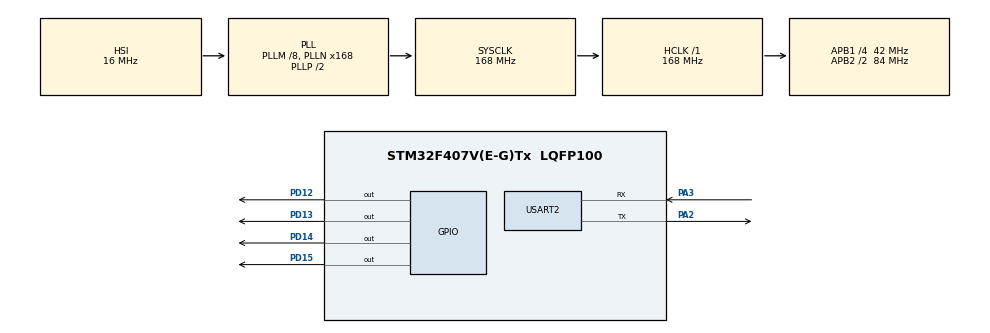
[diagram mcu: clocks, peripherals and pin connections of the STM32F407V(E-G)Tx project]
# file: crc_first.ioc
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Mcu.Family=STM32F4
Mcu.Name=STM32F407V(E-G)Tx
Mcu.Package=LQFP100
NVIC.PriorityGroup=NVIC_PRIORITYGROUP_4
NVIC.TIM1_UP_TIM10_IRQn=true\:0\:0\:false\:false\:true
NVIC.TimeBase=TIM1_UP_TIM10_IRQn
NVIC.TimeBaseIP=TIM1
PA13.Mode=Serial_Wire
PA13.Signal=SYS_JTMS-SWDIO
PA14.Mode=Serial_Wire
PA14.Signal=SYS_JTCK-SWCLK
PA2.Mode=Asynchronous
PA2.Signal=USART2_TX
PA3.Mode=Asynchronous
PA3.Signal=USART2_RX
PC14-OSC32_IN.Mode=LSE-External-Oscillator
PC14-OSC32_IN.Signal=RCC_OSC32_IN
PC15-OSC32_OUT.Mode=LSE-External-Oscillator
PC15-OSC32_OUT.Signal=RCC_OSC32_OUT
PD12.Signal=GPIO_Output
PD13.Signal=GPIO_Output
PD14.Signal=GPIO_Output
PD15.Signal=GPIO_Output
PH0-OSC_IN.Mode=HSE-External-Oscillator
PH0-OSC_IN.Signal=RCC_OSC_IN
PH1-OSC_OUT.Mode=HSE-External-Oscillator
PH1-OSC_OUT.Signal=RCC_OSC_OUT
ProjectManager.HeapSize=0x200
ProjectManager.StackSize=0x400
ProjectManager.TargetToolchain=MDK-ARM V5
RCC.48MHZClocksFreq_Value=84000000
RCC.AHBFreq_Value=168000000
RCC.APB1CLKDivider=RCC_HCLK_DIV4
RCC.APB1Freq_Value=42000000
RCC.APB1TimFreq_Value=84000000
RCC.APB2CLKDivider=RCC_HCLK_DIV2
RCC.APB2Freq_Value=84000000
RCC.APB2TimFreq_Value=168000000
RCC.CortexFreq_Value=168000000
RCC.HCLKFreq_Value=168000000
RCC.HSE_VALUE=8000000
RCC.HSI_VALUE=16000000
RCC.PLLM=8
RCC.PLLN=168
RCC.SYSCLKFreq_VALUE=168000000
RCC.SYSCLKSource=RCC_SYSCLKSOURCE_PLLCLK
RCC.VCOOutputFreq_Value=336000000
VP_CRC_VS_CRC.Mode=CRC_Activate
VP_SYS_VS_tim1.Mode=TIM1
board=crc_first

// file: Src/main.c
/**
  ******************************************************************************
  * File Name          : main.c
  * Description        : Main program body
  ******************************************************************************
  *
  * COPYRIGHT(c) 2017 STMicroelectronics
  *
  * Redistribution and use in source and binary forms, with or without modification,
  * are permitted provided that the following conditions are met:
  *   1. Redistributions of source code must retain the above copyright notice,
  *      this list of conditions and the following disclaimer.
  *   2. Redistributions in binary form must reproduce the above copyright notice,
  *      this list of conditions and the following disclaimer in the documentation
  *      and/or other materials provided with the distribution.
  *   3. Neither the name of STMicroelectronics nor the names of its contributors
  *      may be used to endorse or promote products derived from this software
  *      without specific prior written permission.
  *
  * THIS SOFTWARE IS PROVIDED BY THE COPYRIGHT HOLDERS AND CONTRIBUTORS "AS IS"
  * AND ANY EXPRESS OR IMPLIED WARRANTIES, INCLUDING, BUT NOT LIMITED TO, THE
  * IMPLIED WARRANTIES OF MERCHANTABILITY AND FITNESS FOR A PARTICULAR PURPOSE ARE
  * DISCLAIMED. IN NO EVENT SHALL THE COPYRIGHT HOLDER OR CONTRIBUTORS BE LIABLE
  * FOR ANY DIRECT, INDIRECT, INCIDENTAL, SPECIAL, EXEMPLARY, OR CONSEQUENTIAL
  * DAMAGES (INCLUDING, BUT NOT LIMITED TO, PROCUREMENT OF SUBSTITUTE GOODS OR
  * SERVICES; LOSS OF USE, DATA, OR PROFITS; OR BUSINESS INTERRUPTION) HOWEVER
  * CAUSED AND ON ANY THEORY OF LIABILITY, WHETHER IN CONTRACT, STRICT LIABILITY,
  * OR TORT (INCLUDING NEGLIGENCE OR OTHERWISE) ARISING IN ANY WAY OUT OF THE USE
  * OF THIS SOFTWARE, EVEN IF ADVISED OF THE POSSIBILITY OF SUCH DAMAGE.
  *
  ******************************************************************************
  */
#include "stm32f4xx_hal.h"
#include "crc.h"
#include "usart.h"
#include "gpio.h"
#include "CRC32.h"
/* USER CODE BEGIN Includes */
uint32_t crc_nominal __attribute__((at(0x08007FFC)));
#define ROM_START 0x08000000
#define ROM_LEN   0x00007FFC
/* USER CODE END Includes */

/* USER CODE BEGIN PV */
/* Private variables ---------------------------------------------------------*/

/* USER CODE END PV */

void SystemClock_Config(void);
void Error_Handler(void);

/* USER CODE BEGIN PFP */
/* Private function prototypes -----------------------------------------------*/

/* USER CODE END PFP */

uint32_t crc_actual = 0;
int main(void)
{

  /* MCU Configuration----------------------------------------------------------*/

  /* Reset of all peripherals, Initializes the Flash interface and the Systick. */
  HAL_Init();

  /* Configure the system clock */
  SystemClock_Config();

  /* Initialize all configured peripherals */
  MX_GPIO_Init();
  MX_CRC_Init();
  MX_USART2_UART_Init();
	crc_actual = crc32_fdl(0,(void*)ROM_START,ROM_LEN);
	if(crc_nominal!=crc_actual)
	{
		HAL_UART_Transmit(&huart2,(uint8_t *) "not_equal", 10, 100);
	}
	else
	{
		HAL_UART_Transmit(&huart2,(uint8_t *) "equal", 6, 100);
	}

  /* Infinite loop */
  while (1)
  {

  }

}

/** System Clock Configuration
*/
void SystemClock_Config(void)
{

  RCC_OscInitTypeDef RCC_OscInitStruct;
  RCC_ClkInitTypeDef RCC_ClkInitStruct;

  __HAL_RCC_PWR_CLK_ENABLE();

  __HAL_PWR_VOLTAGESCALING_CONFIG(PWR_REGULATOR_VOLTAGE_SCALE1);

  RCC_OscInitStruct.OscillatorType = RCC_OSCILLATORTYPE_HSI;
  RCC_OscInitStruct.HSIState = RCC_HSI_ON;
  RCC_OscInitStruct.HSICalibrationValue = 16;
  RCC_OscInitStruct.PLL.PLLState = RCC_PLL_ON;
  RCC_OscInitStruct.PLL.PLLSource = RCC_PLLSOURCE_HSI;
  RCC_OscInitStruct.PLL.PLLM = 8;
  RCC_OscInitStruct.PLL.PLLN = 168;
  RCC_OscInitStruct.PLL.PLLP = RCC_PLLP_DIV2;
  RCC_OscInitStruct.PLL.PLLQ = 4;
  if (HAL_RCC_OscConfig(&RCC_OscInitStruct) != HAL_OK)
  {
    Error_Handler();
  }

  RCC_ClkInitStruct.ClockType = RCC_CLOCKTYPE_HCLK|RCC_CLOCKTYPE_SYSCLK
                              |RCC_CLOCKTYPE_PCLK1|RCC_CLOCKTYPE_PCLK2;
  RCC_ClkInitStruct.SYSCLKSource = RCC_SYSCLKSOURCE_PLLCLK;
  RCC_ClkInitStruct.AHBCLKDivider = RCC_SYSCLK_DIV1;
  RCC_ClkInitStruct.APB1CLKDivider = RCC_HCLK_DIV4;
  RCC_ClkInitStruct.APB2CLKDivider = RCC_HCLK_DIV2;
  if (HAL_RCC_ClockConfig(&RCC_ClkInitStruct, FLASH_LATENCY_5) != HAL_OK)
  {
    Error_Handler();
  }

  HAL_SYSTICK_Config(HAL_RCC_GetHCLKFreq()/1000);

  HAL_SYSTICK_CLKSourceConfig(SYSTICK_CLKSOURCE_HCLK);

  /* SysTick_IRQn interrupt configuration */
  HAL_NVIC_SetPriority(SysTick_IRQn, 0, 0);
}

void HAL_TIM_PeriodElapsedCallback(TIM_HandleTypeDef *htim)
{
  if (htim->Instance == TIM1) {
    HAL_IncTick();
  }
}

void Error_Handler(void)
{
  while(1)
  {
  }
}

/************************ (C) COPYRIGHT STMicroelectronics *****END OF FILE****/
